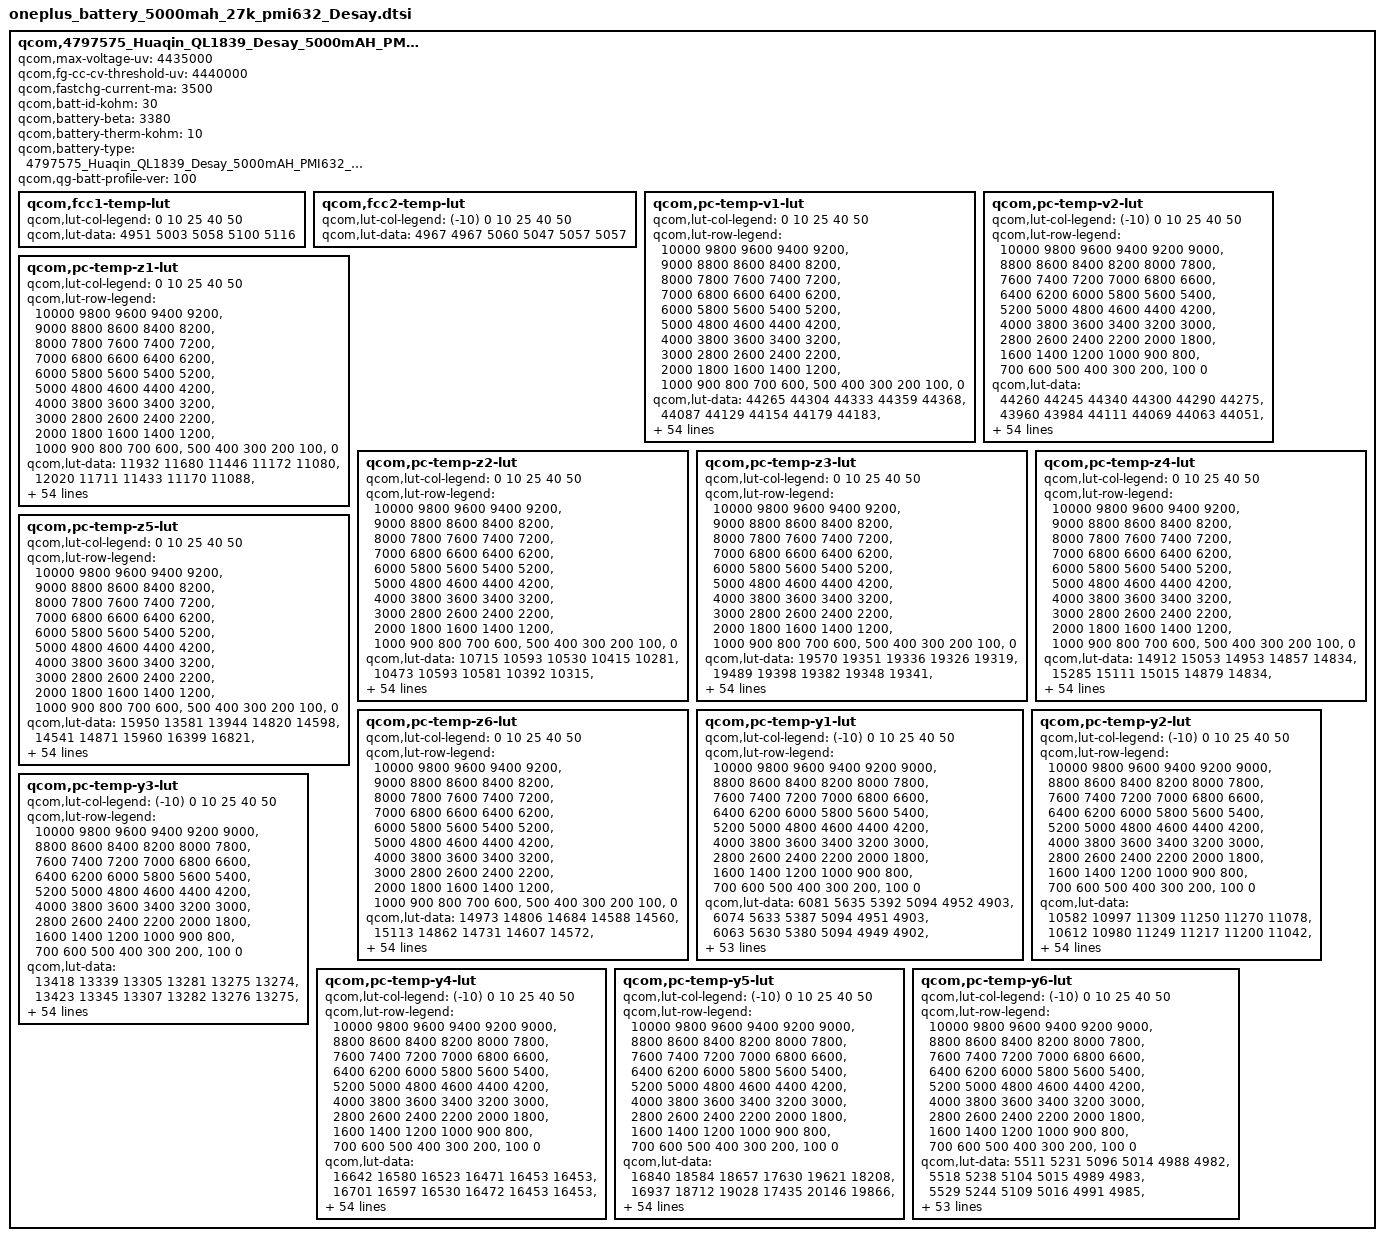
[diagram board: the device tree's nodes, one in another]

qcom,4797575_Huaqin_QL1839_Desay_5000mAH_PMI632 {
    /* 4797575_Huaqin_QL1839_Desay_5000mAH_PMI632_averaged_MasterSlave_Sep28th2020 */
    qcom,max-voltage-uv = <4435000>;
    qcom,fg-cc-cv-threshold-uv = <4440000>;
    qcom,fastchg-current-ma = <3500>;
    qcom,batt-id-kohm = <30>;
    qcom,battery-beta = <3380>;
    qcom,battery-therm-kohm = <10>;
    qcom,battery-type = "4797575_Huaqin_QL1839_Desay_5000mAH_PMI632_averaged_MasterSlave_Sep28th2020";
    qcom,qg-batt-profile-ver = <100>;

	qcom,fcc1-temp-lut {
		qcom,lut-col-legend = <0 10 25 40 50>;
		qcom,lut-data = <4951 5003 5058 5100 5116>;
	};

	qcom,fcc2-temp-lut {
		qcom,lut-col-legend = <(-10) 0 10 25 40 50>;
		qcom,lut-data = <4967 4967 5060 5047 5057 5057>;
	};

	qcom,pc-temp-v1-lut {
		qcom,lut-col-legend = <0 10 25 40 50>;
		qcom,lut-row-legend = <10000 9800 9600 9400 9200>,
			<9000 8800 8600 8400 8200>,
			<8000 7800 7600 7400 7200>,
			<7000 6800 6600 6400 6200>,
			<6000 5800 5600 5400 5200>,
			<5000 4800 4600 4400 4200>,
			<4000 3800 3600 3400 3200>,
			<3000 2800 2600 2400 2200>,
			<2000 1800 1600 1400 1200>,
			<1000 900 800 700 600>,
			<500 400 300 200 100>,
			<0>;
		qcom,lut-data = <44265 44304 44333 44359 44368>,
			<44087 44129 44154 44179 44183>,
			<43919 43952 43970 43998 44004>,
			<43733 43762 43780 43804 43813>,
			<43512 43550 43575 43600 43611>,
			<43270 43324 43354 43387 43399>,
			<43028 43086 43118 43162 43175>,
			<42782 42839 42869 42923 42940>,
			<42535 42592 42618 42675 42697>,
			<42289 42346 42372 42429 42453>,
			<42046 42102 42128 42184 42206>,
			<41807 41862 41886 41941 41961>,
			<41575 41625 41644 41699 41720>,
			<41347 41393 41408 41461 41483>,
			<41124 41166 41184 41229 41251>,
			<40907 40946 40968 41002 41023>,
			<40692 40734 40756 40785 40802>,
			<40484 40529 40550 40578 40590>,
			<40284 40335 40351 40379 40386>,
			<40091 40155 40166 40192 40195>,
			<39907 39960 39976 40009 40012>,
			<39733 39712 39734 39787 39800>,
			<39555 39448 39442 39495 39525>,
			<39328 39231 39212 39239 39273>,
			<39068 39032 39049 39078 39107>,
			<38874 38873 38915 38952 38977>,
			<38757 38768 38798 38831 38849>,
			<38665 38686 38697 38719 38721>,
			<38590 38603 38602 38612 38605>,
			<38527 38521 38509 38509 38502>,
			<38470 38447 38424 38413 38410>,
			<38416 38377 38347 38328 38324>,
			<38367 38313 38277 38252 38246>,
			<38322 38255 38212 38182 38172>,
			<38281 38203 38152 38116 38102>,
			<38240 38155 38095 38054 38035>,
			<38202 38115 38044 37992 37965>,
			<38162 38075 37997 37932 37892>,
			<38101 38016 37932 37858 37807>,
			<38013 37925 37841 37762 37703>,
			<37908 37818 37734 37650 37586>,
			<37783 37697 37616 37531 37461>,
			<37637 37557 37480 37397 37325>,
			<37468 37387 37318 37236 37165>,
			<37315 37238 37173 37097 37030>,
			<37204 37138 37077 37016 36957>,
			<37176 37114 37056 36989 36935>,
			<37148 37093 37035 36975 36916>,
			<37129 37071 37019 36955 36895>,
			<37086 37035 36969 36893 36823>,
			<36896 36816 36719 36615 36528>,
			<36448 36371 36276 36165 36075>,
			<35858 35777 35683 35577 35485>,
			<35038 34958 34868 34764 34672>,
			<33724 33652 33593 33495 33399>,
			<30000 30000 30000 30000 30000>;
	};

	qcom,pc-temp-v2-lut {
		qcom,lut-col-legend = <(-10) 0 10 25 40 50>;
		qcom,lut-row-legend = <10000 9800 9600 9400 9200 9000>,
			<8800 8600 8400 8200 8000 7800>,
			<7600 7400 7200 7000 6800 6600>,
			<6400 6200 6000 5800 5600 5400>,
			<5200 5000 4800 4600 4400 4200>,
			<4000 3800 3600 3400 3200 3000>,
			<2800 2600 2400 2200 2000 1800>,
			<1600 1400 1200 1000 900 800>,
			<700 600 500 400 300 200>,
			<100 0>;
		qcom,lut-data = <44260 44245 44340 44300 44290 44275>,
			<43960 43984 44111 44069 44063 44051>,
			<43680 43733 43887 43843 43840 43830>,
			<43424 43496 43673 43625 43624 43616>,
			<43191 43274 43468 43415 43416 43409>,
			<42960 43047 43254 43197 43200 43194>,
			<42721 42805 43017 42962 42967 42963>,
			<42481 42558 42771 42718 42725 42724>,
			<42241 42313 42524 42474 42482 42482>,
			<42003 42068 42275 42226 42235 42235>,
			<41767 41829 42028 41981 41991 41991>,
			<41530 41600 41786 41741 41749 41749>,
			<41284 41377 41548 41504 41510 41510>,
			<41032 41159 41313 41270 41275 41276>,
			<40784 40947 41084 41040 41046 41047>,
			<40539 40728 40862 40817 40823 40825>,
			<40279 40482 40656 40602 40609 40612>,
			<40005 40207 40447 40393 40403 40405>,
			<39749 39935 40211 40197 40208 40211>,
			<39525 39682 39955 40012 40022 40026>,
			<39327 39460 39704 39802 39815 39819>,
			<39143 39262 39453 39531 39560 39566>,
			<38970 39079 39223 39262 39307 39315>,
			<38804 38912 39035 39056 39098 39107>,
			<38647 38761 38874 38882 38912 38923>,
			<38495 38625 38728 38734 38757 38768>,
			<38348 38499 38597 38607 38628 38638>,
			<38213 38383 38477 38494 38514 38523>,
			<38109 38273 38365 38388 38407 38414>,
			<38030 38164 38260 38288 38308 38313>,
			<37972 38060 38167 38196 38220 38222>,
			<37922 37968 38086 38111 38142 38141>,
			<37871 37900 38008 38034 38067 38063>,
			<37814 37852 37927 37965 37990 37985>,
			<37756 37814 37847 37903 37911 37905>,
			<37698 37778 37786 37833 37823 37810>,
			<37637 37740 37740 37755 37727 37695>,
			<37566 37692 37693 37672 37628 37581>,
			<37483 37629 37633 37589 37534 37483>,
			<37390 37551 37561 37505 37441 37391>,
			<37289 37457 37470 37414 37347 37297>,
			<37184 37343 37353 37313 37251 37198>,
			<37092 37190 37218 37192 37128 37073>,
			<37006 37026 37071 37048 36982 36926>,
			<36923 36924 36954 36929 36876 36824>,
			<36829 36848 36887 36884 36845 36794>,
			<36777 36812 36860 36871 36833 36782>,
			<36682 36760 36830 36852 36819 36767>,
			<36540 36677 36785 36827 36793 36738>,
			<36329 36524 36683 36743 36695 36621>,
			<36079 36256 36432 36484 36382 36286>,
			<35754 35854 35972 35982 35870 35769>,
			<35241 35266 35297 35329 35202 35095>,
			<34385 34412 34341 34422 34257 34134>,
			<32840 32950 32783 33025 32920 32831>,
			<27984 27932 27768 27671 27750 27802>;
	};

	qcom,pc-temp-z1-lut {
		qcom,lut-col-legend = <0 10 25 40 50>;
		qcom,lut-row-legend = <10000 9800 9600 9400 9200>,
			<9000 8800 8600 8400 8200>,
			<8000 7800 7600 7400 7200>,
			<7000 6800 6600 6400 6200>,
			<6000 5800 5600 5400 5200>,
			<5000 4800 4600 4400 4200>,
			<4000 3800 3600 3400 3200>,
			<3000 2800 2600 2400 2200>,
			<2000 1800 1600 1400 1200>,
			<1000 900 800 700 600>,
			<500 400 300 200 100>,
			<0>;
		qcom,lut-data = <11932 11680 11446 11172 11080>,
			<12020 11711 11433 11170 11088>,
			<12285 11831 11425 11166 11086>,
			<12379 11876 11415 11164 11084>,
			<12364 11862 11405 11162 11081>,
			<12351 11845 11395 11157 11078>,
			<12341 11833 11385 11151 11075>,
			<12328 11820 11375 11146 11073>,
			<12309 11804 11367 11142 11071>,
			<12290 11782 11361 11140 11070>,
			<12271 11765 11357 11139 11069>,
			<12245 11755 11353 11137 11068>,
			<12222 11748 11350 11135 11067>,
			<12209 11745 11347 11134 11067>,
			<12201 11744 11346 11133 11067>,
			<12192 11742 11346 11132 11067>,
			<12181 11738 11346 11132 11067>,
			<12174 11731 11345 11133 11067>,
			<12169 11728 11345 11134 11068>,
			<12163 11728 11346 11134 11069>,
			<12163 11728 11348 11135 11069>,
			<12176 11729 11349 11136 11070>,
			<12191 11732 11351 11137 11071>,
			<12192 11735 11353 11138 11072>,
			<12183 11738 11356 11139 11073>,
			<12177 11741 11359 11141 11076>,
			<12180 11744 11362 11144 11078>,
			<12184 11749 11367 11147 11081>,
			<12194 11753 11372 11150 11084>,
			<12206 11758 11378 11154 11086>,
			<12210 11764 11383 11158 11089>,
			<12205 11769 11387 11162 11092>,
			<12201 11774 11390 11165 11096>,
			<12203 11776 11394 11169 11099>,
			<12212 11778 11399 11172 11103>,
			<12221 11781 11405 11176 11107>,
			<12236 11786 11410 11180 11110>,
			<12248 11793 11416 11184 11112>,
			<12253 11803 11422 11187 11115>,
			<12268 11818 11428 11191 11117>,
			<12279 11828 11433 11194 11120>,
			<12278 11831 11439 11197 11123>,
			<12278 11834 11445 11200 11125>,
			<12294 11845 11451 11203 11128>,
			<12306 11856 11461 11207 11130>,
			<12320 11869 11464 11209 11130>,
			<12299 11868 11469 11209 11130>,
			<12310 11873 11468 11210 11130>,
			<12303 11859 11467 11212 11132>,
			<12306 11878 11473 11215 11135>,
			<12340 11892 11482 11220 11139>,
			<12331 11888 11493 11226 11144>,
			<12347 11902 11500 11234 11153>,
			<12370 11926 11517 11248 11165>,
			<12370 11926 11517 11248 11165>,
			<12370 11926 11517 11248 11165>;
	};

	qcom,pc-temp-z2-lut {
		qcom,lut-col-legend = <0 10 25 40 50>;
		qcom,lut-row-legend = <10000 9800 9600 9400 9200>,
			<9000 8800 8600 8400 8200>,
			<8000 7800 7600 7400 7200>,
			<7000 6800 6600 6400 6200>,
			<6000 5800 5600 5400 5200>,
			<5000 4800 4600 4400 4200>,
			<4000 3800 3600 3400 3200>,
			<3000 2800 2600 2400 2200>,
			<2000 1800 1600 1400 1200>,
			<1000 900 800 700 600>,
			<500 400 300 200 100>,
			<0>;
		qcom,lut-data = <10715 10593 10530 10415 10281>,
			<10473 10593 10581 10392 10315>,
			<10366 10560 11029 10457 10362>,
			<10335 10539 11566 10604 10324>,
			<10333 10523 11810 10625 10300>,
			<10322 10504 11886 10515 10328>,
			<10298 10469 11580 10417 10372>,
			<10269 10427 10889 10399 10353>,
			<10248 10395 10466 10390 10261>,
			<10232 10364 10430 10376 10200>,
			<10219 10348 10417 10345 10142>,
			<10209 10354 10416 10303 10125>,
			<10206 10367 10422 10245 10142>,
			<10208 10382 10445 10201 10170>,
			<10215 10406 10798 10205 10187>,
			<10225 10429 11322 10228 10198>,
			<10240 10446 11520 10248 10212>,
			<10261 10461 11616 10268 10237>,
			<10283 10474 11633 10291 10266>,
			<10303 10484 11179 10311 10301>,
			<10318 10498 10596 10333 10346>,
			<10328 10549 10962 10365 10374>,
			<10339 10611 13281 10419 10383>,
			<10368 10619 14706 10448 10389>,
			<10416 10597 13078 10432 10401>,
			<10442 10577 10777 10409 10433>,
			<10445 10561 10466 10414 10514>,
			<10446 10547 10541 10438 10759>,
			<10443 10547 10599 10474 10920>,
			<10437 10558 10648 10555 10775>,
			<10432 10572 10683 10643 10505>,
			<10429 10584 10684 10632 10352>,
			<10425 10597 10679 10529 10248>,
			<10424 10611 10677 10443 10207>,
			<10427 10627 10686 10387 10225>,
			<10431 10639 10701 10350 10264>,
			<10436 10644 10718 10371 10325>,
			<10440 10648 10740 10454 10430>,
			<10441 10653 10770 10526 10520>,
			<10439 10666 10824 10584 10601>,
			<10436 10674 10863 10624 10653>,
			<10424 10666 10867 10629 10646>,
			<10411 10655 10863 10621 10621>,
			<10401 10652 10838 10614 10599>,
			<10480 10700 10792 10613 10574>,
			<10520 10723 10788 10604 10536>,
			<10519 10697 10712 10596 10537>,
			<10517 10644 10714 10606 10523>,
			<10496 10660 10707 10659 10562>,
			<10554 10835 10785 10733 10688>,
			<10519 10775 10814 10635 10509>,
			<10424 10714 10768 10343 10215>,
			<10292 10672 10682 10288 10159>,
			<10126 10516 10577 10203 10096>,
			<10126 10516 10577 10203 10096>,
			<10126 10516 10577 10203 10096>;
	};

	qcom,pc-temp-z3-lut {
		qcom,lut-col-legend = <0 10 25 40 50>;
		qcom,lut-row-legend = <10000 9800 9600 9400 9200>,
			<9000 8800 8600 8400 8200>,
			<8000 7800 7600 7400 7200>,
			<7000 6800 6600 6400 6200>,
			<6000 5800 5600 5400 5200>,
			<5000 4800 4600 4400 4200>,
			<4000 3800 3600 3400 3200>,
			<3000 2800 2600 2400 2200>,
			<2000 1800 1600 1400 1200>,
			<1000 900 800 700 600>,
			<500 400 300 200 100>,
			<0>;
		qcom,lut-data = <19570 19351 19336 19326 19319>,
			<19489 19398 19382 19348 19341>,
			<19533 19462 19397 19363 19349>,
			<19593 19496 19409 19381 19364>,
			<19634 19508 19432 19390 19375>,
			<19654 19515 19460 19394 19383>,
			<19660 19519 19466 19397 19389>,
			<19663 19521 19456 19403 19392>,
			<19661 19521 19444 19408 19394>,
			<19657 19513 19433 19406 19392>,
			<19652 19504 19423 19398 19388>,
			<19646 19495 19417 19391 19384>,
			<19638 19486 19414 19386 19380>,
			<19629 19481 19412 19382 19375>,
			<19619 19478 19420 19379 19372>,
			<19611 19475 19432 19376 19369>,
			<19605 19471 19433 19372 19366>,
			<19600 19466 19428 19367 19363>,
			<19591 19462 19419 19361 19359>,
			<19578 19457 19400 19357 19355>,
			<19571 19455 19380 19353 19350>,
			<19576 19468 19380 19352 19347>,
			<19582 19489 19389 19354 19343>,
			<19590 19492 19392 19355 19338>,
			<19600 19486 19384 19346 19329>,
			<19604 19480 19377 19331 19319>,
			<19599 19473 19375 19330 19324>,
			<19592 19466 19373 19341 19372>,
			<19587 19464 19373 19355 19406>,
			<19582 19466 19381 19374 19402>,
			<19578 19468 19391 19392 19393>,
			<19576 19470 19396 19393 19384>,
			<19574 19472 19400 19384 19375>,
			<19572 19473 19401 19375 19367>,
			<19571 19472 19399 19367 19356>,
			<19570 19470 19396 19359 19346>,
			<19568 19467 19392 19353 19341>,
			<19565 19462 19387 19349 19338>,
			<19562 19458 19382 19345 19336>,
			<19556 19455 19379 19341 19333>,
			<19550 19451 19377 19340 19331>,
			<19544 19447 19376 19341 19335>,
			<19537 19442 19375 19345 19345>,
			<19526 19436 19370 19347 19348>,
			<19485 19415 19360 19345 19348>,
			<19462 19401 19355 19333 19336>,
			<19436 19385 19346 19332 19322>,
			<19427 19366 19347 19323 19320>,
			<19348 19350 19338 19320 19314>,
			<19337 19318 19333 19316 19314>,
			<19335 19353 19338 19341 19339>,
			<19352 19337 19333 19353 19347>,
			<19332 19330 19335 19346 19343>,
			<19334 19333 19342 19348 19343>,
			<19334 19333 19342 19348 19343>,
			<19334 19333 19342 19348 19343>;
	};

	qcom,pc-temp-z4-lut {
		qcom,lut-col-legend = <0 10 25 40 50>;
		qcom,lut-row-legend = <10000 9800 9600 9400 9200>,
			<9000 8800 8600 8400 8200>,
			<8000 7800 7600 7400 7200>,
			<7000 6800 6600 6400 6200>,
			<6000 5800 5600 5400 5200>,
			<5000 4800 4600 4400 4200>,
			<4000 3800 3600 3400 3200>,
			<3000 2800 2600 2400 2200>,
			<2000 1800 1600 1400 1200>,
			<1000 900 800 700 600>,
			<500 400 300 200 100>,
			<0>;
		qcom,lut-data = <14912 15053 14953 14857 14834>,
			<15285 15111 15015 14879 14834>,
			<15492 15151 14978 14872 14841>,
			<15497 15144 14924 14848 14829>,
			<15378 15068 14857 14826 14814>,
			<15255 14982 14792 14804 14793>,
			<15158 14925 14773 14783 14772>,
			<15076 14878 14769 14760 14753>,
			<15010 14843 14764 14739 14738>,
			<14956 14818 14751 14725 14726>,
			<14912 14797 14734 14714 14716>,
			<14876 14777 14722 14706 14708>,
			<14845 14759 14715 14701 14703>,
			<14820 14746 14705 14696 14698>,
			<14800 14737 14677 14691 14694>,
			<14786 14732 14645 14685 14688>,
			<14773 14729 14637 14680 14684>,
			<14764 14727 14634 14675 14679>,
			<14763 14724 14634 14672 14675>,
			<14768 14717 14647 14671 14674>,
			<14769 14713 14673 14670 14674>,
			<14757 14730 14709 14678 14680>,
			<14744 14762 14760 14745 14741>,
			<14767 14788 14795 14803 14801>,
			<14828 14822 14816 14813 14810>,
			<14859 14844 14827 14818 14813>,
			<14861 14838 14825 14814 14801>,
			<14862 14822 14811 14790 14736>,
			<14859 14808 14794 14759 14687>,
			<14848 14794 14773 14724 14681>,
			<14837 14780 14752 14692 14678>,
			<14827 14767 14733 14682 14675>,
			<14818 14756 14716 14677 14672>,
			<14809 14751 14707 14675 14670>,
			<14800 14748 14703 14676 14669>,
			<14792 14745 14701 14676 14669>,
			<14783 14741 14702 14677 14669>,
			<14775 14737 14703 14679 14670>,
			<14769 14736 14706 14682 14673>,
			<14763 14735 14714 14695 14688>,
			<14757 14735 14720 14707 14702>,
			<14747 14725 14715 14704 14698>,
			<14735 14712 14706 14698 14688>,
			<14723 14704 14704 14699 14691>,
			<14699 14685 14692 14692 14685>,
			<14686 14667 14669 14673 14666>,
			<14704 14672 14665 14667 14668>,
			<14708 14681 14649 14657 14656>,
			<14789 14692 14641 14638 14636>,
			<14795 14720 14640 14633 14625>,
			<14793 14690 14665 14647 14648>,
			<14787 14718 14681 14650 14656>,
			<14814 14728 14680 14659 14663>,
			<14823 14732 14676 14659 14663>,
			<14823 14732 14676 14659 14663>,
			<14823 14732 14676 14659 14663>;
	};

	qcom,pc-temp-z5-lut {
		qcom,lut-col-legend = <0 10 25 40 50>;
		qcom,lut-row-legend = <10000 9800 9600 9400 9200>,
			<9000 8800 8600 8400 8200>,
			<8000 7800 7600 7400 7200>,
			<7000 6800 6600 6400 6200>,
			<6000 5800 5600 5400 5200>,
			<5000 4800 4600 4400 4200>,
			<4000 3800 3600 3400 3200>,
			<3000 2800 2600 2400 2200>,
			<2000 1800 1600 1400 1200>,
			<1000 900 800 700 600>,
			<500 400 300 200 100>,
			<0>;
		qcom,lut-data = <15950 13581 13944 14820 14598>,
			<14541 14871 15960 16399 16821>,
			<14369 16003 16414 17280 17260>,
			<14789 16768 16894 18861 18586>,
			<15596 17264 18253 19671 19800>,
			<16373 17742 20537 19983 20944>,
			<16905 18419 21304 20444 22026>,
			<17392 19143 21314 21890 23080>,
			<17919 19472 21276 23676 24034>,
			<18532 19577 21200 24026 24472>,
			<19266 19719 21097 24043 25475>,
			<20107 20124 21182 24082 26351>,
			<20969 20836 21930 24332 26500>,
			<21767 21618 23338 24771 26609>,
			<22541 22522 28825 25697 27106>,
			<23714 23287 36297 27250 28501>,
			<25781 23869 39194 27980 30051>,
			<27775 24350 40527 28102 31789>,
			<27630 24613 40710 28225 33335>,
			<25701 24547 34277 28551 34008>,
			<25501 24805 26064 29124 34409>,
			<30196 34902 28018 29590 34236>,
			<36788 50257 36434 29719 30487>,
			<43831 51812 39282 29169 25243>,
			<51739 43521 31907 24569 20579>,
			<54759 35906 23709 18232 16438>,
			<50004 31365 21340 17092 16942>,
			<43453 27802 19855 17372 25631>,
			<39448 27158 19451 17933 32012>,
			<36713 27528 20460 22129 32303>,
			<35453 28159 22219 28089 32354>,
			<35043 29670 24408 30110 32382>,
			<34820 32127 27363 31021 32622>,
			<34975 34441 30312 31310 32708>,
			<35920 37006 33799 31225 31024>,
			<37102 38468 36072 31048 28957>,
			<38577 38666 36003 30813 28867>,
			<39853 38730 35474 30425 29459>,
			<40209 38610 34664 29735 29644>,
			<40368 38121 32878 27500 26878>,
			<40354 37440 31014 25294 23915>,
			<38719 36139 29949 24618 24461>,
			<36453 34583 28955 24307 26261>,
			<34764 33610 26807 24640 27125>,
			<31561 31922 26576 24822 27930>,
			<28696 30671 27846 22088 23889>,
			<21001 23611 24780 22033 18881>,
			<19472 19312 27427 21058 19562>,
			<13286 16856 25160 24562 22806>,
			<12932 13943 23904 24492 28088>,
			<13120 17694 20821 26416 27139>,
			<13653 15046 16840 25340 23683>,
			<12658 14265 16486 20223 19568>,
			<12450 14167 16844 18789 17715>,
			<12450 14167 16844 18789 17715>,
			<12450 14167 16844 18789 17715>;
	};

	qcom,pc-temp-z6-lut {
		qcom,lut-col-legend = <0 10 25 40 50>;
		qcom,lut-row-legend = <10000 9800 9600 9400 9200>,
			<9000 8800 8600 8400 8200>,
			<8000 7800 7600 7400 7200>,
			<7000 6800 6600 6400 6200>,
			<6000 5800 5600 5400 5200>,
			<5000 4800 4600 4400 4200>,
			<4000 3800 3600 3400 3200>,
			<3000 2800 2600 2400 2200>,
			<2000 1800 1600 1400 1200>,
			<1000 900 800 700 600>,
			<500 400 300 200 100>,
			<0>;
		qcom,lut-data = <14973 14806 14684 14588 14560>,
			<15113 14862 14731 14607 14572>,
			<15322 14943 14720 14611 14580>,
			<15373 14968 14706 14611 14582>,
			<15320 14932 14691 14609 14582>,
			<15261 14889 14676 14601 14578>,
			<15207 14860 14665 14592 14572>,
			<15155 14834 14655 14586 14567>,
			<15111 14812 14645 14579 14561>,
			<15074 14791 14632 14572 14555>,
			<15042 14773 14619 14563 14548>,
			<15014 14756 14610 14555 14542>,
			<14989 14742 14605 14549 14537>,
			<14967 14733 14599 14544 14532>,
			<14948 14726 14592 14540 14528>,
			<14934 14721 14585 14535 14524>,
			<14923 14716 14580 14531 14520>,
			<14914 14712 14576 14525 14516>,
			<14908 14707 14573 14521 14512>,
			<14903 14702 14570 14517 14508>,
			<14901 14699 14569 14515 14505>,
			<14899 14714 14579 14518 14507>,
			<14898 14739 14613 14549 14532>,
			<14913 14752 14630 14573 14554>,
			<14946 14765 14632 14573 14554>,
			<14963 14772 14633 14569 14551>,
			<14962 14768 14631 14566 14548>,
			<14961 14759 14625 14562 14547>,
			<14958 14752 14620 14558 14544>,
			<14952 14748 14616 14554 14540>,
			<14947 14745 14612 14551 14535>,
			<14943 14742 14608 14546 14530>,
			<14939 14739 14604 14541 14525>,
			<14936 14738 14601 14536 14519>,
			<14934 14738 14599 14532 14513>,
			<14932 14737 14598 14529 14508>,
			<14930 14736 14596 14526 14505>,
			<14928 14734 14594 14523 14504>,
			<14928 14733 14594 14523 14503>,
			<14929 14734 14597 14527 14507>,
			<14929 14735 14599 14531 14512>,
			<14928 14732 14598 14531 14514>,
			<14926 14728 14594 14531 14515>,
			<14924 14725 14592 14532 14518>,
			<14908 14713 14584 14529 14516>,
			<14897 14702 14573 14515 14501>,
			<14892 14696 14567 14511 14496>,
			<14889 14692 14561 14503 14488>,
			<14886 14689 14553 14493 14476>,
			<14888 14688 14552 14488 14471>,
			<14892 14697 14566 14509 14496>,
			<14905 14706 14573 14519 14507>,
			<14916 14713 14577 14522 14510>,
			<14936 14725 14583 14526 14514>,
			<14936 14725 14583 14526 14514>,
			<14936 14725 14583 14526 14514>;
	};

	qcom,pc-temp-y1-lut {
		qcom,lut-col-legend = <(-10) 0 10 25 40 50>;
		qcom,lut-row-legend = <10000 9800 9600 9400 9200 9000>,
			<8800 8600 8400 8200 8000 7800>,
			<7600 7400 7200 7000 6800 6600>,
			<6400 6200 6000 5800 5600 5400>,
			<5200 5000 4800 4600 4400 4200>,
			<4000 3800 3600 3400 3200 3000>,
			<2800 2600 2400 2200 2000 1800>,
			<1600 1400 1200 1000 900 800>,
			<700 600 500 400 300 200>,
			<100 0>;
		qcom,lut-data = <6081 5635 5392 5094 4952 4903>,
			<6074 5633 5387 5094 4951 4903>,
			<6063 5630 5380 5094 4949 4902>,
			<6052 5627 5372 5092 4947 4901>,
			<6043 5626 5365 5089 4946 4900>,
			<6039 5625 5360 5086 4945 4899>,
			<6031 5623 5356 5081 4944 4898>,
			<6022 5621 5351 5076 4943 4898>,
			<6021 5619 5347 5073 4942 4897>,
			<6017 5614 5341 5071 4940 4896>,
			<6014 5610 5337 5069 4938 4895>,
			<6015 5614 5333 5068 4937 4895>,
			<6018 5619 5331 5067 4936 4894>,
			<6021 5619 5328 5066 4936 4894>,
			<6026 5617 5324 5063 4936 4893>,
			<6028 5616 5322 5062 4936 4893>,
			<6025 5618 5318 5064 4936 4894>,
			<6020 5619 5314 5065 4936 4894>,
			<6017 5617 5313 5065 4936 4895>,
			<6014 5616 5313 5065 4936 4895>,
			<6014 5620 5313 5065 4936 4896>,
			<6022 5621 5313 5066 4937 4896>,
			<6033 5619 5312 5068 4938 4896>,
			<6031 5617 5313 5070 4938 4896>,
			<6017 5615 5315 5072 4938 4897>,
			<6008 5614 5318 5075 4939 4898>,
			<6006 5615 5323 5078 4941 4900>,
			<6005 5614 5327 5081 4944 4902>,
			<6012 5614 5328 5083 4946 4904>,
			<6031 5614 5328 5085 4948 4905>,
			<6049 5614 5328 5088 4950 4906>,
			<6048 5618 5332 5092 4953 4908>,
			<6032 5627 5335 5097 4955 4910>,
			<6019 5632 5340 5101 4957 4912>,
			<6017 5627 5345 5104 4959 4914>,
			<6018 5625 5349 5107 4961 4916>,
			<6021 5630 5354 5109 4963 4917>,
			<6028 5636 5356 5111 4965 4918>,
			<6037 5636 5356 5113 4966 4920>,
			<6036 5631 5356 5115 4967 4921>,
			<6027 5628 5357 5117 4968 4923>,
			<6009 5633 5362 5120 4970 4924>,
			<6006 5634 5366 5124 4972 4925>,
			<6014 5630 5382 5128 4973 4927>,
			<5989 5629 5382 5135 4976 4928>,
			<6004 5634 5388 5134 4979 4931>,
			<5999 5650 5387 5138 4979 4930>,
			<6013 5647 5394 5138 4979 4931>,
			<6055 5650 5396 5140 4978 4931>,
			<6030 5637 5401 5142 4979 4931>,
			<6048 5643 5405 5140 4981 4934>,
			<6101 5646 5409 5146 4985 4938>,
			<6110 5660 5414 5161 4991 4942>,
			<6181 5709 5427 5180 5001 4951>,
			<6181 5709 5427 5180 5001 4951>,
			<6181 5709 5427 5180 5001 4951>;
	};

	qcom,pc-temp-y2-lut {
		qcom,lut-col-legend = <(-10) 0 10 25 40 50>;
		qcom,lut-row-legend = <10000 9800 9600 9400 9200 9000>,
			<8800 8600 8400 8200 8000 7800>,
			<7600 7400 7200 7000 6800 6600>,
			<6400 6200 6000 5800 5600 5400>,
			<5200 5000 4800 4600 4400 4200>,
			<4000 3800 3600 3400 3200 3000>,
			<2800 2600 2400 2200 2000 1800>,
			<1600 1400 1200 1000 900 800>,
			<700 600 500 400 300 200>,
			<100 0>;
		qcom,lut-data = <10582 10997 11309 11250 11270 11078>,
			<10612 10980 11249 11217 11200 11042>,
			<10641 10948 11191 11175 11130 11006>,
			<10668 10913 11137 11128 11064 10971>,
			<10692 10883 11089 11086 11006 10936>,
			<10710 10870 11048 11056 10960 10903>,
			<10723 10870 11010 11025 10923 10866>,
			<10734 10872 10981 10993 10892 10834>,
			<10744 10876 10972 10977 10872 10820>,
			<10754 10888 10967 10981 10858 10812>,
			<10761 10905 10966 10992 10844 10809>,
			<10780 10923 10987 11014 10822 10798>,
			<10826 10945 11022 11042 10805 10780>,
			<10862 10974 11055 11061 10805 10767>,
			<10901 11034 11091 11081 10815 10752>,
			<10908 11098 11135 11107 10830 10746>,
			<10880 11136 11200 11146 10885 10758>,
			<10858 11149 11262 11200 10962 10784>,
			<10871 11135 11297 11304 11059 10843>,
			<10896 11119 11323 11480 11214 10957>,
			<10911 11116 11329 11550 11307 11038>,
			<10916 11119 11318 11486 11348 11087>,
			<10917 11121 11303 11414 11367 11118>,
			<10912 11127 11306 11395 11342 11138>,
			<10898 11140 11326 11385 11291 11165>,
			<10879 11151 11342 11388 11277 11179>,
			<10859 11159 11363 11451 11311 11195>,
			<10839 11159 11378 11514 11358 11218>,
			<10819 11152 11382 11536 11399 11258>,
			<10797 11145 11389 11558 11449 11339>,
			<10770 11137 11403 11587 11504 11408>,
			<10721 11120 11438 11639 11588 11459>,
			<10489 11099 11459 11682 11637 11507>,
			<10113 11083 11444 11707 11589 11571>,
			<9813 11072 11412 11734 11515 11637>,
			<9724 11062 11397 11740 11498 11645>,
			<9705 11046 11392 11691 11472 11586>,
			<9693 11013 11386 11622 11439 11510>,
			<9685 10960 11360 11556 11421 11432>,
			<9680 10894 11312 11496 11408 11358>,
			<9676 10826 11253 11489 11406 11320>,
			<9672 10733 11175 11517 11404 11297>,
			<9670 10381 11091 11488 11387 11286>,
			<9667 9888 11017 11399 11382 11271>,
			<9665 9771 10964 11330 11225 11059>,
			<9663 9729 10918 11296 11064 10902>,
			<9662 9705 10887 11321 11046 10890>,
			<9661 9698 10868 11316 11099 10922>,
			<9659 9690 10852 11370 11157 10936>,
			<9657 9681 10831 11377 11156 10920>,
			<9655 9673 10766 11340 11055 10870>,
			<9653 9665 10618 11202 10920 10779>,
			<9650 9658 10255 11095 10808 10693>,
			<9649 9655 9792 10977 10636 10529>,
			<9649 9655 9792 10977 10636 10529>,
			<9649 9655 9792 10977 10636 10529>;
	};

	qcom,pc-temp-y3-lut {
		qcom,lut-col-legend = <(-10) 0 10 25 40 50>;
		qcom,lut-row-legend = <10000 9800 9600 9400 9200 9000>,
			<8800 8600 8400 8200 8000 7800>,
			<7600 7400 7200 7000 6800 6600>,
			<6400 6200 6000 5800 5600 5400>,
			<5200 5000 4800 4600 4400 4200>,
			<4000 3800 3600 3400 3200 3000>,
			<2800 2600 2400 2200 2000 1800>,
			<1600 1400 1200 1000 900 800>,
			<700 600 500 400 300 200>,
			<100 0>;
		qcom,lut-data = <13418 13339 13305 13281 13275 13274>,
			<13423 13345 13307 13282 13276 13275>,
			<13430 13350 13311 13283 13278 13276>,
			<13437 13356 13315 13284 13280 13278>,
			<13442 13360 13318 13285 13281 13279>,
			<13445 13363 13319 13286 13282 13280>,
			<13446 13366 13320 13287 13282 13280>,
			<13446 13367 13320 13288 13283 13281>,
			<13446 13367 13320 13288 13283 13281>,
			<13446 13366 13321 13289 13284 13282>,
			<13445 13364 13321 13290 13285 13282>,
			<13445 13363 13322 13294 13285 13283>,
			<13445 13364 13323 13297 13286 13283>,
			<13439 13365 13322 13298 13286 13284>,
			<13424 13367 13321 13297 13287 13284>,
			<13414 13368 13320 13297 13287 13285>,
			<13410 13364 13323 13296 13289 13287>,
			<13406 13357 13326 13296 13292 13289>,
			<13402 13350 13325 13296 13292 13290>,
			<13398 13345 13321 13297 13293 13291>,
			<13394 13341 13317 13298 13293 13291>,
			<13391 13338 13312 13295 13289 13286>,
			<13388 13335 13307 13290 13284 13281>,
			<13385 13332 13304 13287 13281 13278>,
			<13381 13331 13302 13283 13278 13277>,
			<13378 13330 13301 13282 13277 13277>,
			<13374 13329 13301 13283 13277 13277>,
			<13366 13328 13301 13284 13277 13278>,
			<13357 13327 13300 13284 13276 13277>,
			<13353 13324 13299 13284 13275 13276>,
			<13355 13321 13299 13283 13275 13275>,
			<13362 13318 13300 13283 13276 13276>,
			<13369 13318 13301 13283 13278 13276>,
			<13377 13320 13300 13283 13278 13277>,
			<13388 13323 13299 13284 13277 13278>,
			<13403 13327 13298 13284 13277 13278>,
			<13422 13330 13300 13284 13277 13277>,
			<13444 13333 13301 13283 13276 13276>,
			<13471 13335 13302 13283 13276 13276>,
			<13505 13337 13303 13283 13277 13277>,
			<13545 13340 13304 13283 13277 13278>,
			<13594 13344 13305 13284 13279 13279>,
			<13657 13346 13306 13284 13279 13279>,
			<13741 13348 13307 13283 13276 13276>,
			<13843 13366 13309 13282 13275 13275>,
			<13968 13395 13310 13285 13282 13282>,
			<14066 13418 13314 13289 13284 13284>,
			<14133 13437 13319 13292 13288 13286>,
			<14265 13469 13327 13298 13290 13287>,
			<14494 13519 13336 13299 13289 13285>,
			<14893 13590 13342 13297 13284 13282>,
			<15702 13729 13349 13295 13285 13283>,
			<17823 14094 13369 13300 13287 13286>,
			<24512 15503 13477 13308 13293 13292>,
			<24512 15503 13477 13308 13293 13292>,
			<24512 15503 13477 13308 13293 13292>;
	};

	qcom,pc-temp-y4-lut {
		qcom,lut-col-legend = <(-10) 0 10 25 40 50>;
		qcom,lut-row-legend = <10000 9800 9600 9400 9200 9000>,
			<8800 8600 8400 8200 8000 7800>,
			<7600 7400 7200 7000 6800 6600>,
			<6400 6200 6000 5800 5600 5400>,
			<5200 5000 4800 4600 4400 4200>,
			<4000 3800 3600 3400 3200 3000>,
			<2800 2600 2400 2200 2000 1800>,
			<1600 1400 1200 1000 900 800>,
			<700 600 500 400 300 200>,
			<100 0>;
		qcom,lut-data = <16642 16580 16523 16471 16453 16453>,
			<16701 16597 16530 16472 16453 16453>,
			<16768 16622 16539 16473 16452 16453>,
			<16834 16648 16548 16475 16453 16454>,
			<16889 16670 16554 16476 16453 16455>,
			<16924 16680 16556 16478 16454 16455>,
			<16942 16682 16555 16479 16455 16455>,
			<16954 16683 16552 16481 16456 16456>,
			<16961 16687 16553 16483 16457 16456>,
			<16968 16699 16557 16487 16460 16457>,
			<16973 16714 16562 16489 16463 16459>,
			<16972 16733 16570 16491 16466 16461>,
			<16967 16753 16581 16492 16470 16465>,
			<16967 16768 16597 16496 16474 16469>,
			<16976 16786 16620 16507 16480 16473>,
			<16983 16801 16643 16521 16487 16477>,
			<16951 16797 16673 16538 16492 16481>,
			<16866 16759 16694 16557 16500 16486>,
			<16800 16711 16686 16582 16516 16498>,
			<16763 16657 16652 16611 16543 16519>,
			<16740 16623 16614 16620 16552 16526>,
			<16724 16606 16567 16570 16531 16514>,
			<16707 16592 16529 16507 16503 16495>,
			<16686 16581 16517 16485 16482 16478>,
			<16661 16573 16509 16473 16462 16461>,
			<16633 16568 16507 16469 16457 16456>,
			<16606 16564 16507 16471 16459 16457>,
			<16591 16560 16507 16474 16464 16458>,
			<16592 16555 16508 16478 16470 16463>,
			<16599 16547 16511 16484 16479 16472>,
			<16604 16534 16515 16491 16488 16480>,
			<16610 16524 16519 16498 16499 16491>,
			<16628 16521 16521 16505 16506 16499>,
			<16657 16528 16516 16513 16509 16503>,
			<16684 16541 16505 16520 16510 16506>,
			<16701 16559 16504 16521 16508 16504>,
			<16711 16579 16511 16509 16496 16489>,
			<16713 16597 16519 16494 16483 16477>,
			<16708 16612 16526 16486 16476 16475>,
			<16699 16621 16532 16480 16471 16475>,
			<16691 16624 16536 16479 16471 16476>,
			<16686 16623 16538 16483 16476 16480>,
			<16692 16615 16537 16484 16473 16476>,
			<16712 16604 16534 16476 16456 16454>,
			<16748 16613 16525 16468 16448 16444>,
			<16786 16642 16527 16475 16459 16464>,
			<16820 16679 16545 16488 16483 16494>,
			<16795 16697 16571 16511 16513 16528>,
			<16798 16730 16613 16542 16548 16561>,
			<16813 16776 16664 16558 16546 16544>,
			<16868 16818 16680 16531 16487 16482>,
			<17042 16855 16677 16500 16466 16467>,
			<17674 16898 16702 16508 16467 16466>,
			<21289 17354 16812 16536 16475 16471>,
			<21289 17354 16812 16536 16475 16471>,
			<21289 17354 16812 16536 16475 16471>;
	};

	qcom,pc-temp-y5-lut {
		qcom,lut-col-legend = <(-10) 0 10 25 40 50>;
		qcom,lut-row-legend = <10000 9800 9600 9400 9200 9000>,
			<8800 8600 8400 8200 8000 7800>,
			<7600 7400 7200 7000 6800 6600>,
			<6400 6200 6000 5800 5600 5400>,
			<5200 5000 4800 4600 4400 4200>,
			<4000 3800 3600 3400 3200 3000>,
			<2800 2600 2400 2200 2000 1800>,
			<1600 1400 1200 1000 900 800>,
			<700 600 500 400 300 200>,
			<100 0>;
		qcom,lut-data = <16840 18584 18657 17630 19621 18208>,
			<16937 18712 19028 17435 20146 19866>,
			<17100 18751 19189 17089 20463 20851>,
			<17296 18720 19187 16688 20624 21326>,
			<17493 18635 19068 16332 20683 21460>,
			<17659 18514 18877 16117 20687 21412>,
			<17814 18281 18298 15877 20038 20929>,
			<18030 17922 17454 15558 18968 20168>,
			<18313 17490 16795 15303 18311 19600>,
			<18756 16880 16209 15008 17781 19040>,
			<19210 16481 15831 14886 17314 18442>,
			<19785 16549 15490 15396 16912 17758>,
			<20008 17003 15201 16054 16518 17080>,
			<19488 17672 15096 15938 16007 16520>,
			<19165 18755 14952 15135 15379 16011>,
			<19753 19737 14957 14497 15134 15840>,
			<21108 20628 15956 14129 15260 16132>,
			<22192 21577 17666 13899 15423 16461>,
			<21860 22139 19924 14285 15501 16339>,
			<21454 22340 22850 15918 15571 15896>,
			<21669 22352 23825 17844 15885 15817>,
			<22209 22223 23054 20536 18934 17420>,
			<22662 21973 22034 22653 21923 19152>,
			<22862 21863 21327 21968 21581 19585>,
			<23081 22096 20738 19600 20043 19838>,
			<23232 22505 20620 18701 18862 19918>,
			<22620 22878 20872 19366 18123 19458>,
			<19765 23194 21082 20000 17470 18738>,
			<16787 23420 20949 19967 16687 17612>,
			<15583 23032 20707 19722 15910 16146>,
			<15718 21588 20972 19584 15793 15797>,
			<16590 19899 22774 19579 16640 15895>,
			<16680 19147 24163 19659 17590 16093>,
			<15628 19544 23922 20320 18105 17050>,
			<14694 20293 23170 21763 18528 18698>,
			<14736 21181 22867 22700 19083 19375>,
			<14981 21763 23037 23334 19907 19544>,
			<15125 21914 23175 23613 20558 19720>,
			<15267 21807 22836 22940 20673 20341>,
			<15321 21689 22054 21771 20431 21282>,
			<14964 21942 21103 21072 20311 21769>,
			<14321 22339 19916 20340 20684 21955>,
			<14059 20141 19405 19859 20659 22255>,
			<13964 15866 19327 19889 19894 22258>,
			<13964 14842 19606 19004 17169 18035>,
			<14007 14634 19155 18108 18243 18081>,
			<14304 14606 18546 18413 17373 16554>,
			<14936 14831 18298 17877 17301 15944>,
			<15758 15805 18558 18993 17028 15754>,
			<16532 16929 19271 19035 16373 15289>,
			<17173 17687 20030 19969 17027 16113>,
			<16145 17678 19416 19957 17858 16803>,
			<12270 15872 17099 20566 17813 17066>,
			<9708 12184 14390 21679 21882 22697>,
			<9708 12184 14390 21679 21882 22697>,
			<9708 12184 14390 21679 21882 22697>;
	};

	qcom,pc-temp-y6-lut {
		qcom,lut-col-legend = <(-10) 0 10 25 40 50>;
		qcom,lut-row-legend = <10000 9800 9600 9400 9200 9000>,
			<8800 8600 8400 8200 8000 7800>,
			<7600 7400 7200 7000 6800 6600>,
			<6400 6200 6000 5800 5600 5400>,
			<5200 5000 4800 4600 4400 4200>,
			<4000 3800 3600 3400 3200 3000>,
			<2800 2600 2400 2200 2000 1800>,
			<1600 1400 1200 1000 900 800>,
			<700 600 500 400 300 200>,
			<100 0>;
		qcom,lut-data = <5511 5231 5096 5014 4988 4982>,
			<5518 5238 5104 5015 4989 4983>,
			<5529 5244 5109 5016 4991 4985>,
			<5540 5250 5111 5017 4992 4986>,
			<5549 5254 5112 5018 4993 4988>,
			<5553 5255 5112 5019 4994 4988>,
			<5552 5254 5110 5019 4995 4989>,
			<5550 5252 5107 5020 4995 4990>,
			<5548 5251 5107 5021 4996 4990>,
			<5545 5250 5106 5022 4997 4991>,
			<5543 5250 5106 5024 4998 4992>,
			<5541 5252 5108 5026 5000 4993>,
			<5536 5256 5110 5028 5001 4994>,
			<5531 5260 5113 5031 5003 4996>,
			<5523 5265 5118 5033 5005 4997>,
			<5515 5268 5123 5036 5007 4999>,
			<5503 5265 5132 5041 5010 5001>,
			<5480 5248 5140 5046 5014 5004>,
			<5461 5230 5137 5053 5019 5009>,
			<5449 5211 5124 5062 5027 5015>,
			<5443 5199 5110 5065 5029 5017>,
			<5439 5192 5093 5048 5020 5009>,
			<5436 5186 5079 5027 5008 4999>,
			<5432 5183 5074 5018 4999 4993>,
			<5428 5181 5071 5012 4992 4987>,
			<5425 5181 5070 5011 4990 4985>,
			<5421 5181 5070 5012 4990 4985>,
			<5420 5182 5071 5014 4991 4986>,
			<5422 5182 5072 5015 4993 4987>,
			<5431 5181 5073 5017 4995 4989>,
			<5446 5179 5075 5019 4998 4991>,
			<5466 5177 5078 5021 5002 4994>,
			<5488 5179 5081 5024 5005 4997>,
			<5510 5186 5080 5027 5006 4999>,
			<5534 5198 5078 5030 5006 5001>,
			<5563 5212 5078 5031 5006 5001>,
			<5594 5229 5082 5027 5002 4995>,
			<5628 5246 5088 5023 4998 4992>,
			<5662 5264 5093 5022 4997 4992>,
			<5700 5284 5098 5020 4996 4992>,
			<5742 5305 5103 5020 4996 4993>,
			<5789 5327 5108 5023 4999 4996>,
			<5850 5345 5114 5023 4998 4994>,
			<5929 5365 5121 5021 4991 4986>,
			<6032 5403 5126 5020 4989 4984>,
			<6159 5459 5130 5025 4998 4995>,
			<6254 5503 5144 5032 5006 5004>,
			<6307 5534 5161 5041 5017 5016>,
			<6421 5582 5187 5054 5029 5026>,
			<6620 5652 5216 5059 5028 5020>,
			<6973 5745 5236 5051 5007 5000>,
			<7694 5900 5260 5041 5003 4998>,
			<9487 6237 5328 5051 5006 5001>,
			<15039 7497 5517 5069 5013 5008>,
			<15039 7497 5517 5069 5013 5008>,
			<15039 7497 5517 5069 5013 5008>;
	};

};
